# GD32F20x_CL register map
File version: 1.0
CPU: CM3 r2p1, little endian, no MPU, no FPU, 4 interrupt priority bits
Registers are 32-bit, read-write, reset 0x0 unless marked. A register's access mark holds for its fields unless they carry their own. Offsets are from the block's base; [hi:lo] are bit positions; 'fields as' and 'values as' point back to an identical list.

## USBFS_GLOBAL — USB full speed global registers
Base 0x50000000
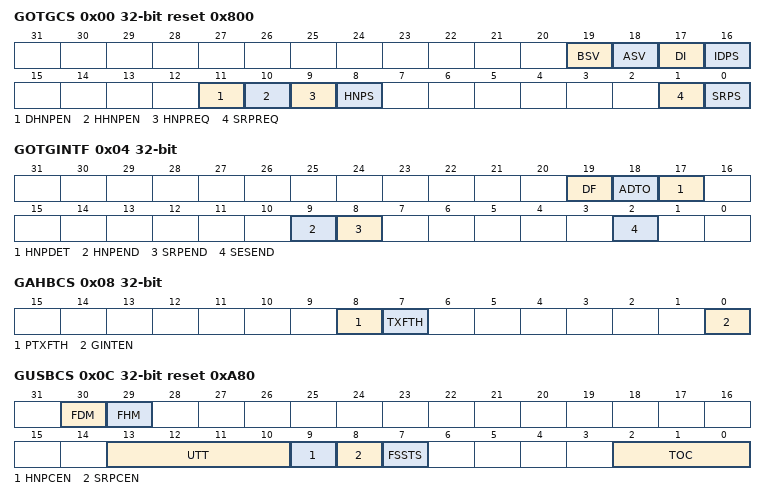
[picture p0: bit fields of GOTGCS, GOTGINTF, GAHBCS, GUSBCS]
0x00 GOTGCS access per field reset 0x800 — Global OTG control and status register (USBFS_GOTGCS)
  [19] BSV ro — B-session valid
  [18] ASV ro — A-session valid
  [17] DI ro — Debounce interval
  [16] IDPS ro — ID pin status
  [11] DHNPEN rw — Device HNP enabled
  [10] HHNPEN rw — Host HNP enable
  [9] HNPREQ rw — HNP request
  [8] HNPS ro — Host success
  [1] SRPREQ rw — SRP request
  [0] SRPS ro — SRP success
0x04 GOTGINTF — Global OTG interrupt flag register (USBFS_GOTGINTF)
  [19] DF — Debounce finish
  [18] ADTO — A-device timeout
  [17] HNPDET — Host negotiation request detected
  [9] HNPEND
  [8] SRPEND — Session request success status change
  [2] SESEND — Session end
0x08 GAHBCS — Global AHB control and status register (USBFS_GAHBCS)
  [8] PTXFTH — Periodic Tx FIFO threshold
  [7] TXFTH — Tx FIFO threshold
  [0] GINTEN — Global interrupt enable
0x0C GUSBCS access per field reset 0xA80 — Global USB control and status register (OTG_FS_GUSBCSR)
  [30] FDM rw — Force device mode
  [29] FHM rw — Force host mode
  [13:10] UTT rw — USB turnaround time
  [9] HNPCEN rw — HNP capability enable
  [8] SRPCEN rw — SRP capability enable
  [7] FSSTS ro — Full speed serial transceiver select
  [2:0] TOC rw — Timeout calibration
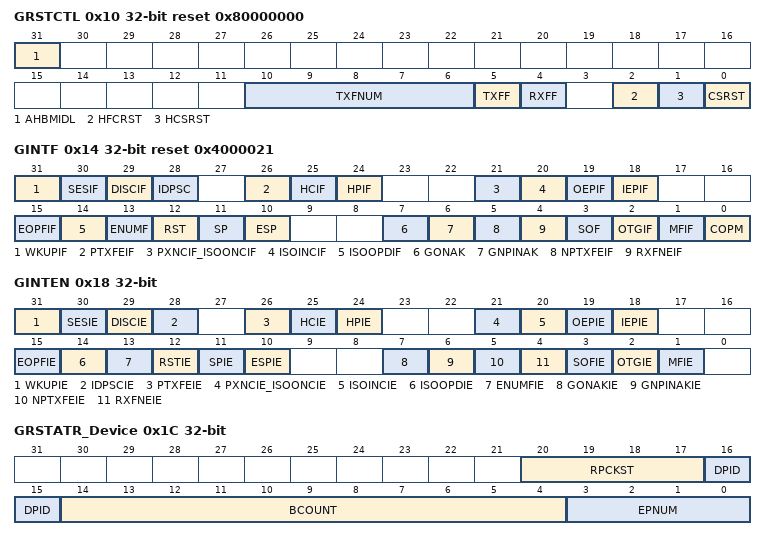
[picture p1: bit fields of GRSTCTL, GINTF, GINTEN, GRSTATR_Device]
0x10 GRSTCTL access per field reset 0x80000000 — Global reset control register (USBFS_GRSTCTL)
  [31] AHBMIDL ro — AHB master idle
  [10:6] TXFNUM rw — TxFIFO number
  [5] TXFF rw — TxFIFO flush
  [4] RXFF rw — RxFIFO flush
  [2] HFCRST rw — Host frame counter reset
  [1] HCSRST rw — HCLK soft reset
  [0] CSRST rw — Core soft reset
0x14 GINTF access per field reset 0x4000021 — Global interrupt flag register (USBFS_GINTF)
  [31] WKUPIF rw — Wakeup interrupt flag
  [30] SESIF rw — Session interrupt flag
  [29] DISCIF rw — Disconnect interrupt flag
  [28] IDPSC rw — ID pin status change
  [26] PTXFEIF ro — Periodic TxFIFO empty interrupt flag
  [25] HCIF ro — Host channels interrupt flag
  [24] HPIF ro — Host port interrupt flag
  [21] PXNCIF_ISOONCIF rw — periodic transfer not complete interrupt flag(Host mode)/isochronous OUT transfer not complete interrupt flag(Device mode)
  [20] ISOINCIF rw — Isochronous IN transfer Not Complete Interrupt Flag
  [19] OEPIF ro — OUT endpoint interrupt flag
  [18] IEPIF ro — IN endpoint interrupt flag
  [15] EOPFIF rw — End of periodic frame interrupt flag
  [14] ISOOPDIF rw — Isochronous OUT packet dropped interrupt
  [13] ENUMF rw — Enumeration finished
  [12] RST rw — USB reset
  [11] SP rw — USB suspend
  [10] ESP rw — Early suspend
  [7] GONAK ro — Global OUT NAK effective
  [6] GNPINAK ro — Global Non-Periodic IN NAK effective
  [5] NPTXFEIF ro — Non-periodic TxFIFO empty interrupt flag
  [4] RXFNEIF ro — RxFIFO non-empty interrupt flag
  [3] SOF rw — Start of frame
  [2] OTGIF ro — OTG interrupt flag
  [1] MFIF rw — Mode fault interrupt flag
  [0] COPM ro — Current operation mode
0x18 GINTEN access per field — Global interrupt enable register (USBFS_GINTEN)
  [31] WKUPIE rw — Wakeup interrupt enable
  [30] SESIE rw — Session interrupt enable
  [29] DISCIE rw — Disconnect interrupt enable
  [28] IDPSCIE rw — ID pin status change interrupt enable
  [26] PTXFEIE rw — Periodic TxFIFO empty interrupt enable
  [25] HCIE rw — Host channels interrupt enable
  [24] HPIE ro — Host port interrupt enable
  [21] PXNCIE_ISOONCIE rw — periodic transfer not compelete Interrupt enable(Host mode)/isochronous OUT transfer not complete interrupt enable(Device mode)
  [20] ISOINCIE rw — isochronous IN transfer not complete interrupt enable
  [19] OEPIE rw — OUT endpoints interrupt enable
  [18] IEPIE rw — IN endpoints interrupt enable
  [15] EOPFIE rw — End of periodic frame interrupt enable
  [14] ISOOPDIE rw — Isochronous OUT packet dropped interrupt enable
  [13] ENUMFIE rw — Enumeration finish interrupt enable
  [12] RSTIE rw — USB reset interrupt enable
  [11] SPIE rw — USB suspend interrupt enable
  [10] ESPIE rw — Early suspend interrupt enable
  [7] GONAKIE rw — Global OUT NAK effective interrupt enable
  [6] GNPINAKIE rw — Global non-periodic IN NAK effective interrupt enable
  [5] NPTXFEIE rw — Non-periodic TxFIFO empty interrupt enable
  [4] RXFNEIE rw — Receive FIFO non-empty interrupt enable
  [3] SOFIE rw — Start of frame interrupt enable
  [2] OTGIE rw — OTG interrupt enable
  [1] MFIE rw — Mode fault interrupt enable
0x1C GRSTATR_Device ro — Global Receive status read(Device mode)
  [20:17] RPCKST — Recieve packet status
  [16:15] DPID — Data PID
  [14:4] BCOUNT — Byte count
  [3:0] EPNUM — Endpoint number
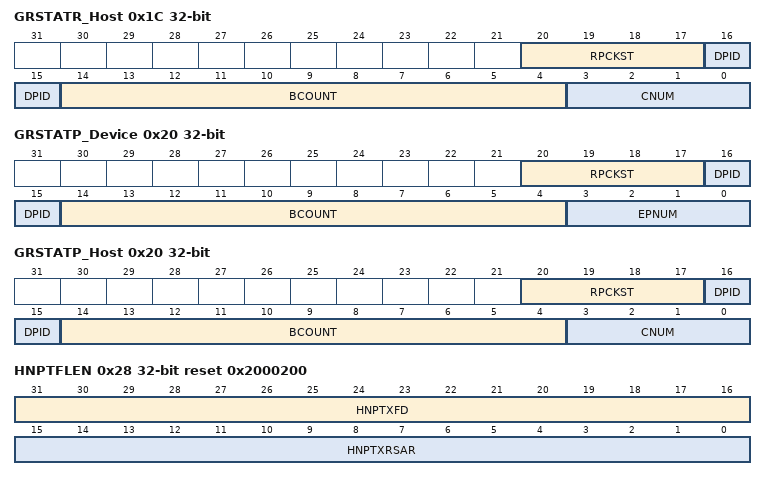
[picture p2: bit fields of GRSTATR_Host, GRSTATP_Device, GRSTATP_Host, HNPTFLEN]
0x1C GRSTATR_Host ro (alternate view of GRSTATR_Device) — Global Receive status read(Host mode)
  [20:17] RPCKST — Reivece packet status
  [16:15] DPID — Data PID
  [14:4] BCOUNT — Byte count
  [3:0] CNUM — Channel number
0x20 GRSTATP_Device ro — Global Receive status pop(Device mode)
  fields as GRSTATR_Device
0x20 GRSTATP_Host ro (alternate view of GRSTATP_Device) — Global Receive status pop(Host mode)
  fields as GRSTATR_Host
0x24 GRFLEN reset 0x200 — Global Receive FIFO size register (USBFS_GRFLEN)
  [15:0] RXFD — Rx FIFO depth
0x28 HNPTFLEN reset 0x2000200 — Host non-periodic transmit FIFO length register (Host mode)
  [31:16] HNPTXFD — host non-periodic TxFIFO depth
  [15:0] HNPTXRSAR — host non-periodic transmit Tx RAM start address
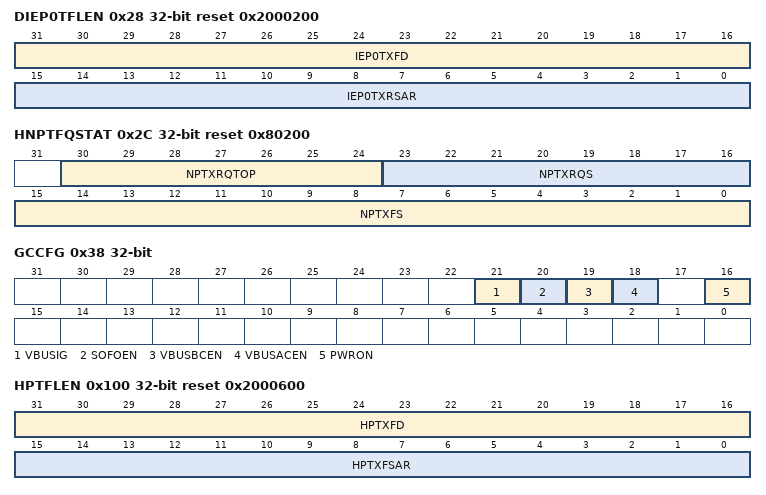
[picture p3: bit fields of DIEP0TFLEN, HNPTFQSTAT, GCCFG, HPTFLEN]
0x28 DIEP0TFLEN reset 0x2000200 (alternate view of HNPTFLEN) — Device IN endpoint 0 transmit FIFO length (Device mode)
  [31:16] IEP0TXFD — in endpoint 0 Tx FIFO depth
  [15:0] IEP0TXRSAR — in endpoint 0 Tx RAM start address
0x2C HNPTFQSTAT ro reset 0x80200 — Host non-periodic transmit FIFO/queue status register (HNPTFQSTAT)
  [30:24] NPTXRQTOP — Top of the non-periodic transmit request queue
  [23:16] NPTXRQS — Non-periodic transmit request queue space
  [15:0] NPTXFS — Non-periodic TxFIFO space
0x38 GCCFG — Global core configuration register (USBFS_GCCFG)
  [21] VBUSIG — VBUS ignored
  [20] SOFOEN — SOF output enable
  [19] VBUSBCEN — The VBUS B-device Comparer enable
  [18] VBUSACEN — The VBUS A-device Comparer enable
  [16] PWRON — Power on
0x3C CID reset 0x1000 — core ID register
  [31:0] CID — Core ID
0x100 HPTFLEN reset 0x2000600 — Host periodic transmit FIFO length register (HPTFLEN)
  [31:16] HPTXFD — Host periodic TxFIFO depth
  [15:0] HPTXFSAR — Host periodic TxFIFO start address
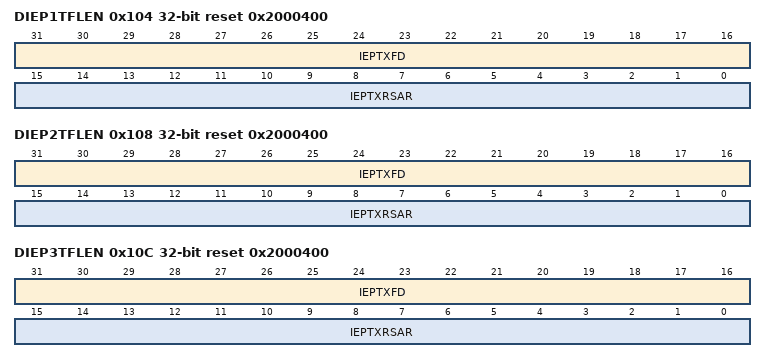
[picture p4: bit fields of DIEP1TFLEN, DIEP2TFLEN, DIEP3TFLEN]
0x104 DIEP1TFLEN reset 0x2000400 — device IN endpoint transmit FIFO size register (DIEP1TFLEN)
  [31:16] IEPTXFD — IN endpoint TxFIFO depth
  [15:0] IEPTXRSAR — IN endpoint FIFO transmit RAM start address
0x108 DIEP2TFLEN reset 0x2000400 — device IN endpoint transmit FIFO size register (DIEP2TFLEN)
  fields as DIEP1TFLEN
0x10C DIEP3TFLEN reset 0x2000400 — device IN endpoint transmit FIFO size register (FS_DIEP3TXFLEN)
  [31:16] IEPTXFD — IN endpoint TxFIFO depth
  [15:0] IEPTXRSAR — IN endpoint FIFO4 transmit RAM start address
